# AVR32DU14 register map
Vendor: Atmel; File version: 1.0
CPU: other r0p0, little endian, no MPU, no FPU, 4 interrupt priority bits
Registers are 8-bit, read-write, reset 0x0 unless marked. A register's access mark holds for its fields unless they carry their own. Offsets are from the block's base; lines under a group give offsets from that group; [hi:lo] are bit positions; {n}, {i} and the like mark numbered series; 'fields as' and 'values as' point back to an identical list; <NAME> marks a mode.

## Memory map
0x00800000 VPORTA size 0x4 — Virtual Ports
0x00800008 VPORTC size 0x4 — Virtual Ports
0x0080000C VPORTD size 0x4 — Virtual Ports
0x00800014 VPORTF size 0x4 — Virtual Ports
0x0080001C GPR size 0x4 — General Purpose Registers
0x00800034 CPU blocks up to offset 0xC
0x00800040 RSTCTRL size 0x2 — Reset controller
0x00800050 SLPCTRL size 0x2 — Sleep Controller
0x00800060 CLKCTRL blocks up to offset 0x26 — Clock controller
0x008000A0 BOD blocks up to offset 0xC — Bod interface
0x008000B0 VREF size 0x1 — Voltage reference
0x00800100 WDT size 0x2 — Watch-Dog Timer
0x00800110 CPUINT size 0x4 — Interrupt Controller
0x00800120 CRCSCAN size 0x3
0x00800140 RTC blocks up to offset 0x17 — Real-Time Counter
0x008001C0 CCL blocks up to offset 0x18 — Configurable Custom Logic
0x00800200 EVSYS blocks up to offset 0x34 — Event System
0x00800400 PORTA blocks up to offset 0x19 — I/O Ports
0x00800440 PORTC blocks up to offset 0x19 — I/O Ports
0x00800460 PORTD blocks up to offset 0x19 — I/O Ports
0x008004A0 PORTF blocks up to offset 0x19 — I/O Ports
0x008005E0 PORTMUX blocks up to offset 0x8 — Port Multiplexer
0x00800600 ADC0 size 0x15 — Analog to Digital Converter
0x00800680 AC0 blocks up to offset 0x8 — Analog Comparator
0x00800800 USART0 size 0xF — Universal Synchronous and Asynchronous Receiver and Transmitter
0x00800820 USART1 size 0xF — Universal Synchronous and Asynchronous Receiver and Transmitter
0x00800900 TWI0 blocks up to offset 0xF — Two-Wire Interface
0x00800940 SPI0 size 0x5 — Serial Peripheral Interface
0x00800A00 TCA0 blocks up to offset 0x3E — 16-bit Timer/Counter Type A
0x00800B00 TCB0 blocks up to offset 0xE — 16-bit Timer Type B
0x00800B10 TCB1 blocks up to offset 0xE — 16-bit Timer Type B
0x00800C00 USB0 size 0xC — USB Device Controller
0x00800F01 SYSCFG blocks up to offset 0x6 — System Configuration Registers
0x00801000 NVMCTRL blocks up to offset 0x10 — Non-volatile Memory Controller
0x00801040 LOCK size 0x4 — Lockbits
0x00801080 SIGROW blocks up to offset 0x20 — Signature row
0x00801100 BOOTROW size 0x1
0x00801200 USERROW size 0x1

## Interrupts
1 CRCSCAN_NMI (CPU)
2 BOD_VLM (CPU)
3 CLKCTRL_CFD (CPU)
4 RTC_CNT (CPU)
5 RTC_PIT (CPU)
6 CCL_CCL (CPU)
7 USB0_BUSEVENT (CPU)
8 USB0_TRNCOMPL (CPU)
9 PORTA_PORT (CPU)
10 TCA0_LUNF_OVF (CPU)
11 TCA0_HUNF (CPU)
12 TCA0_CMP0_LCMP0 (CPU)
13 TCA0_CMP1_LCMP1 (CPU)
14 TCA0_CMP2_LCMP2 (CPU)
15 TCB0_INT (CPU)
16 TWI0_TWIS (CPU)
17 TWI0_TWIM (CPU)
18 SPI0_INT (CPU)
19 USART0_RXC (CPU)
20 USART0_DRE (CPU)
21 USART0_TXC (CPU)
22 PORTD_PORT (CPU)
23 PORTC_PORT (CPU)
24 PORTF_PORT (CPU)
25 NVMCTRL_NVMREADY (CPU)
26 USART1_RXC (CPU)
27 USART1_DRE (CPU)
28 USART1_TXC (CPU)
29 TCB1_INT (CPU)
30 AC0_AC (CPU)
31 ADC0_ERROR (CPU)
32 ADC0_RESRDY (CPU)
33 ADC0_SAMPRDY (CPU)

## AC0 — Analog Comparator
Base 0x00800680
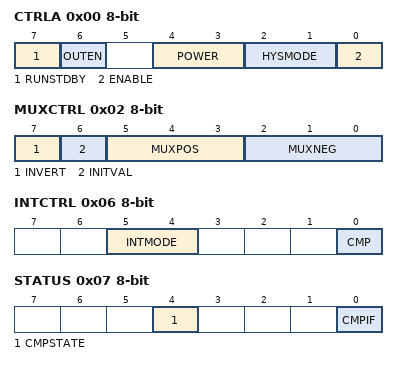
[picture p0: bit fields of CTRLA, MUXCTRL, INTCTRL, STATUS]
0x00 CTRLA — Control A
  [7] RUNSTDBY — Run in Standby Mode
  [6] OUTEN — Output Pad Enable
  [4:3] POWER — Power profile
    0=PROFILE0 (Power profile 0, lowest consumption and highest response time.); 1=PROFILE1 (Power profile 1); 2=PROFILE2 (Power profile 2); 3=PROFILE3 (Power profile 3)
  [2:1] HYSMODE — Hysteresis Mode
    0=NONE (No hysteresis); 1=SMALL (Small hysteresis); 2=MEDIUM (Medium hysteresis); 3=LARGE (Large hysteresis)
  [0] ENABLE
0x02 MUXCTRL — Mux Control A
  [7] INVERT — Invert AC Output
  [6] INITVAL — AC Output Initial Value
    0=LOW (Output initialized to 0); 1=HIGH (Output initialized to 1)
  [5:3] MUXPOS — Positive Input MUX Selection
    0=AINP0 (Positive Pin 0); 3=AINP3 (Positive Pin 3); 4=AINP4 (Positive Pin 4)
  [2:0] MUXNEG — Negative Input MUX Selection
    0=AINN0 (Negative Pin 0); 1=AINN1 (Negative Pin 1); 2=AINN2 (Negative Pin 2); 4=DACREF (DAC Reference)
0x05 DACREF — DAC Voltage Reference
0x06 INTCTRL — Interrupt Control
  [5:4] INTMODE — Interrupt Mode
    0=BOTHEDGE (Positive and negative inputs crosses); 2=NEGEDGE (Positive input goes below negative input); 3=POSEDGE (Positive input goes above negative input)
  [0] CMP — Interrupt Enable
0x07 STATUS
  [4] CMPSTATE ro — Analog Comparator State
  [0] CMPIF — Analog Comparator Interrupt Flag
